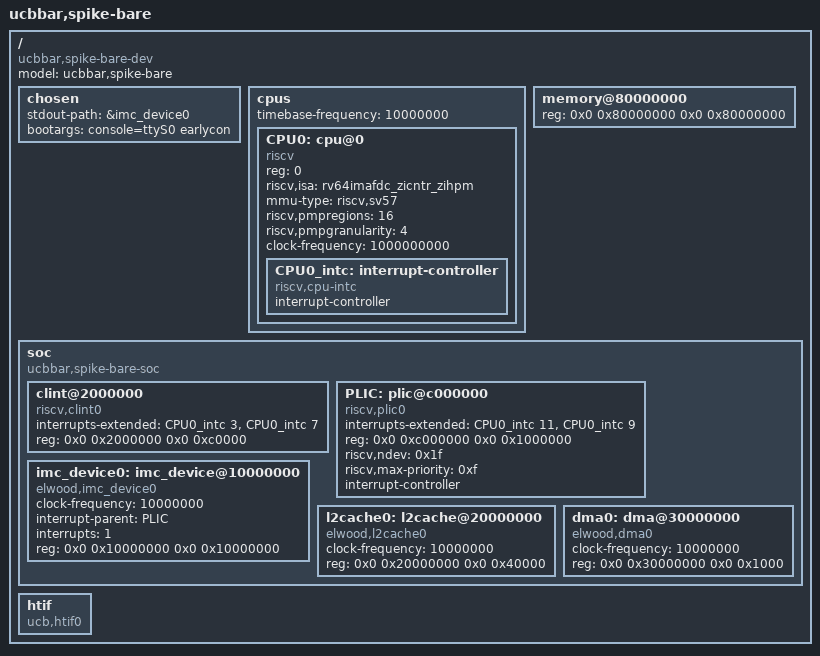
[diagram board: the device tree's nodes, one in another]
/dts-v1/;

/ {
  #address-cells = <2>;
  #size-cells = <2>;
  compatible = "ucbbar,spike-bare-dev";
  model = "ucbbar,spike-bare";
  chosen {
    stdout-path = &imc_device0;
    bootargs = "console=ttyS0 earlycon";
  };
  cpus {
    #address-cells = <1>;
    #size-cells = <0>;
    timebase-frequency = <10000000>;
    CPU0: cpu@0 {
      device_type = "cpu";
      reg = <0>;
      status = "okay";
      compatible = "riscv";
      riscv,isa = "rv64imafdc_zicntr_zihpm";
      mmu-type = "riscv,sv57";
      riscv,pmpregions = <16>;
      riscv,pmpgranularity = <4>;
      clock-frequency = <1000000000>;
      CPU0_intc: interrupt-controller {
        #address-cells = <2>;
        #interrupt-cells = <1>;
        interrupt-controller;
        compatible = "riscv,cpu-intc";
      };
    };
  };
  memory@80000000 {
    device_type = "memory";
    reg = <0x0 0x80000000 0x0 0x80000000>;
  };
  soc {
    #address-cells = <2>;
    #size-cells = <2>;
    compatible = "ucbbar,spike-bare-soc", "simple-bus";
    ranges;
    clint@2000000 {
      compatible = "riscv,clint0";
      interrupts-extended = <&CPU0_intc 3 &CPU0_intc 7 >;
      reg = <0x0 0x2000000 0x0 0xc0000>;
    };
    PLIC: plic@c000000 {
      compatible = "riscv,plic0";
      #address-cells = <2>;
      interrupts-extended = <&CPU0_intc 11 &CPU0_intc 9 >;
      reg = <0x0 0xc000000 0x0 0x1000000>;
      riscv,ndev = <0x1f>;
      riscv,max-priority = <0xf>;
      #interrupt-cells = <1>;
      interrupt-controller;
    };
    imc_device0: imc_device@10000000 {
      compatible = "elwood,imc_device0";
      clock-frequency = <10000000>;
      interrupt-parent = <&PLIC>;
      interrupts = <1>;
      reg = <0x0 0x10000000 0x0 0x10000000>;
    };
    l2cache0: l2cache@20000000 {
      compatible = "elwood,l2cache0";
      clock-frequency = <10000000>;
      reg = <0x0 0x20000000 0x0 0x40000>;
    };
    dma0: dma@30000000 {
      compatible = "elwood,dma0";
      clock-frequency = <10000000>;
      reg = <0x0 0x30000000 0x0 0x1000>;
    };
  };
  htif {
    compatible = "ucb,htif0";
  };
};
